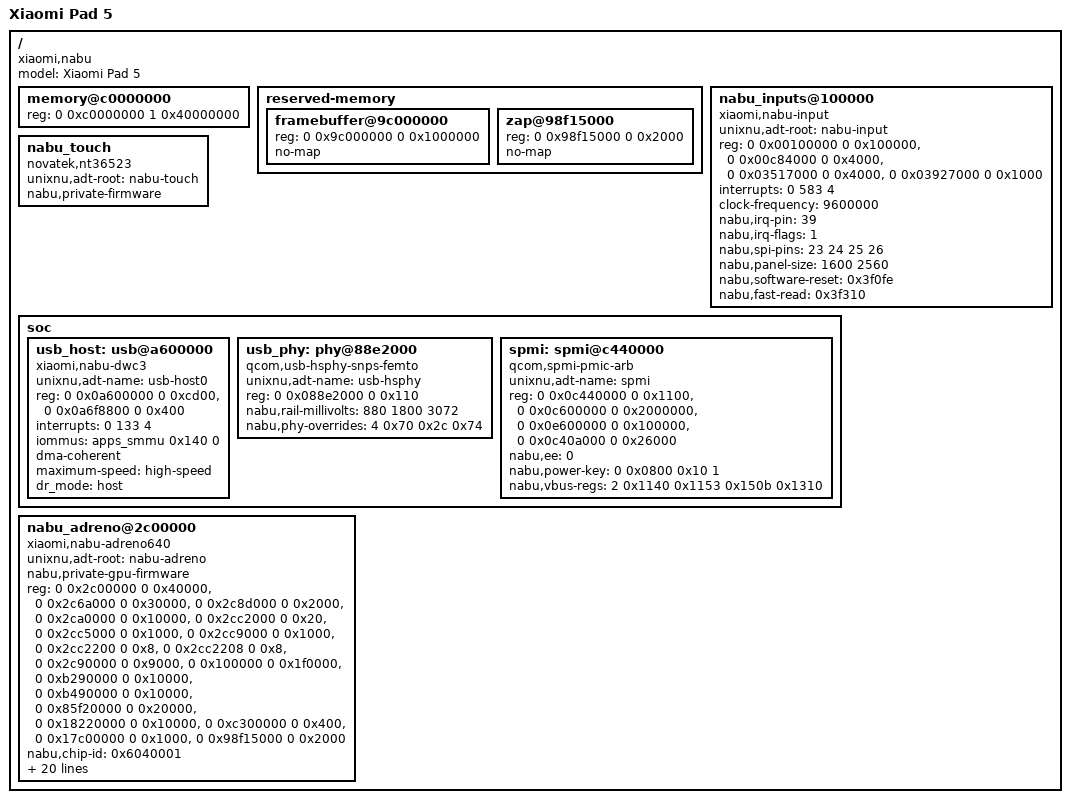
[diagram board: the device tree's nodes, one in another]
// SPDX-License-Identifier: BSD-2-Clause-Patent
/dts-v1/;
/include/ "sm8150.dtsi"
/ {
    model = "Xiaomi Pad 5";
    compatible = "xiaomi,nabu", "qcom,sm8150";
    // The high physical bank, with holes/reservations supplied by DarwinBoot.
    memory@c0000000 { device_type = "memory"; reg = <0 0xc0000000 1 0x40000000>; };
    reserved-memory {
        #address-cells = <2>;
        #size-cells = <2>;
        ranges;
        // Firmware owns the initialized 1600x2560 BGRA scanout.
        framebuffer@9c000000 { reg = <0 0x9c000000 0 0x1000000>; no-map; };
        zap@98f15000 { reg = <0 0x98f15000 0 0x2000>; no-map; };
    };
};

/ {
    // Low-address resources cannot live in arm-io's nonzero SoC window.
    nabu_inputs@100000 {
        unixnu,adt-root = "nabu-input";
        compatible = "xiaomi,nabu-input";
        #address-cells = <2>; #size-cells = <2>;
        reg = <0 0x00100000 0 0x100000>, <0 0x00c84000 0 0x4000>,
              <0 0x03517000 0 0x4000>, <0 0x03927000 0 0x1000>;
        reg-names = "gcc", "geni-se18", "spi-tlmm", "touch-irq-tlmm";
        interrupts = <0 583 4>;
        clock-frequency = <9600000>;
        nabu,irq-pin = <39>;
        nabu,irq-flags = <1>;
        nabu,spi-pins = <23 24 25 26>;
        nabu,panel-size = <1600 2560>;
        nabu,software-reset = <0x3f0fe>;
        nabu,fast-read = <0x3f310>;
    };
    nabu_touch {
        unixnu,adt-root = "nabu-touch";
        compatible = "novatek,nt36523";
        nabu,private-firmware;
    };
    soc {
        usb_host: usb@a600000 {
            unixnu,adt-name = "usb-host0";
            compatible = "xiaomi,nabu-dwc3", "snps,dwc3";
            reg = <0 0x0a600000 0 0xcd00>, <0 0x0a6f8800 0 0x400>;
            reg-names = "core", "qscratch";
            interrupts = <0 133 4>;
            iommus = <&apps_smmu 0x140 0>;
            dma-coherent;
            maximum-speed = "high-speed";
            dr_mode = "host";
        };
        usb_phy: phy@88e2000 {
            unixnu,adt-name = "usb-hsphy";
            compatible = "qcom,usb-hsphy-snps-femto";
            reg = <0 0x088e2000 0 0x110>;
            nabu,rail-millivolts = <880 1800 3072>;
            nabu,phy-overrides = <4 0x70 0x2c 0x74>;
        };
        spmi: spmi@c440000 {
            unixnu,adt-name = "spmi";
            compatible = "qcom,spmi-pmic-arb";
            reg = <0 0x0c440000 0 0x1100>, <0 0x0c600000 0 0x2000000>,
                  <0 0x0e600000 0 0x100000>, <0 0x0c40a000 0 0x26000>;
            reg-names = "core", "chnls", "obsrvr", "cnfg";
            nabu,ee = <0>;
            nabu,power-key = <0 0x0800 0x10 1>;
            nabu,vbus-regs = <2 0x1140 0x1153 0x150b 0x1310>;
        };
    };
};

// A640 resources use absolute root ranges; never inherit arm-io translation.
/ {
    nabu_adreno@2c00000 {
        unixnu,adt-root = "nabu-adreno";
        compatible = "xiaomi,nabu-adreno640";
        nabu,private-gpu-firmware;
        reg = <0 0x2c00000 0 0x40000>, <0 0x2c6a000 0 0x30000>, <0 0x2c8d000 0 0x2000>, <0 0x2ca0000 0 0x10000>, <0 0x2cc2000 0 0x20>, <0 0x2cc5000 0 0x1000>, <0 0x2cc9000 0 0x1000>, <0 0x2cc2200 0 0x8>, <0 0x2cc2208 0 0x8>, <0 0x2c90000 0 0x9000>, <0 0x100000 0 0x1f0000>, <0 0xb290000 0 0x10000>, <0 0xb490000 0 0x10000>, <0 0x85f20000 0 0x20000>, <0 0x18220000 0 0x10000>, <0 0xc300000 0 0x400>, <0 0x17c00000 0 0x1000>, <0 0x98f15000 0 0x2000>;
        reg-names = "gpu", "gmu", "rscc", "smmu", "smmu-tcu", "smmu-tbu-0", "smmu-tbu-1", "smmu-tbu-status-0", "smmu-tbu-status-1", "gpucc", "gcc", "pdc", "pdc-seq", "command-db", "rpmh", "aop", "aop-doorbell", "zap";
        nabu,chip-id = <0x6040001>;
        nabu,gmem-bytes = <0x100000>;
        nabu,frequency-hz = <0xf518240>;
        nabu,highest-bank-bit = <0xf>;
        nabu,min-access-length = <0x20>;
        nabu,ubwc-mode = <0x3>;
        nabu,gpu-bank = <0x0>;
        nabu,gpu-asid = <0x1>;
        nabu,gpu-slot = <0x0>;
        nabu,gpu-sid = <0x0>;
        nabu,gpu-sid-mask = <0x401>;
        nabu,gmu-bank = <0x1>;
        nabu,gmu-asid = <0x2>;
        nabu,gmu-slot = <0x4>;
        nabu,gmu-sid = <0x5>;
        nabu,gmu-sid-mask = <0x400>;
        nabu,aop-doorbell-offset = <0xc>;
        nabu,aop-doorbell-value = <0x1>;
        nabu,zap-pas-id = <0xd>;
        interrupt-names = "gpu", "smmu-global", "smmu-context-0", "smmu-context-1", "smmu-context-2", "smmu-context-3", "smmu-context-4", "smmu-context-5", "smmu-context-6", "smmu-context-7";
        nabu,interrupts = <332 706 713 714 715 716 717 718 719 720>;
    };
};
